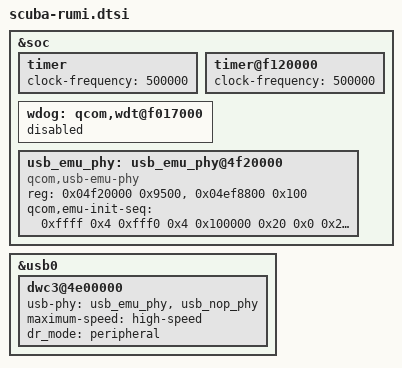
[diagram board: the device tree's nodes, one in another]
&soc {
	timer {
		clock-frequency = <500000>;
	};

	timer@f120000 {
		clock-frequency = <500000>;
	};

	wdog: qcom,wdt@f017000 {
		status = "disabled";
	};

	usb_emu_phy: usb_emu_phy@4f20000 {
			compatible = "qcom,usb-emu-phy";
			reg = <0x04f20000 0x9500>,
				<0x04ef8800 0x100>;
			reg-names = "base", "qscratch_base";

			qcom,emu-init-seq = <0xffff 0x4
					     0xfff0 0x4
					     0x100000 0x20
					     0x0 0x20
					     0x101f0 0x20
					     0x100000 0x3c
					     0x0 0x3c
					     0x10060 0x3c
					     0x0 0x4>;
	};
};

&usb0 {
	dwc3@4e00000 {
		usb-phy = <&usb_emu_phy>, <&usb_nop_phy>;
		maximum-speed = "high-speed";
		dr_mode = "peripheral";
	};
};
